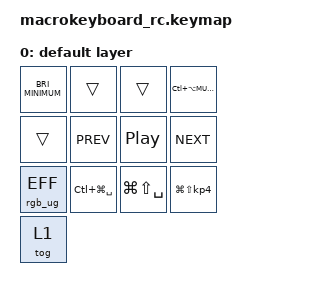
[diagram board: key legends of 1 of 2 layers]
/*
 * Copyright (c) 2021 The ZMK Contributors
 *
 * SPDX-License-Identifier: MIT
 */

#include <behaviors.dtsi>
#include <dt-bindings/zmk/bt.h>
#include <dt-bindings/zmk/keys.h>
#include <dt-bindings/zmk/rgb.h>

#define TIMEOUT 300

&encoder_1 {
    status = "okay";
};

&encoder_2 {
    status = "okay";
};

/ {
    combos {
        compatible = "zmk,combos";

        combo_btclr {
            timeout-ms = <TIMEOUT>;
            key-positions = <1 0>;
            bindings = <&bt BT_CLR>;
        };

        combo_reset {
            timeout-ms = <TIMEOUT>;
            key-positions = <3 2>;
            bindings = <&sys_reset>;
        };

        combo_bootloader {
            timeout-ms = <TIMEOUT>;
            key-positions = <0 3>;
            bindings = <&bootloader>;
        };

        sleep {
            bindings = <&kp LG(LA(K_EJECT))>;
            key-positions = <1 2>;
        };
    };

    behaviors {
        /* DEPRECATED: `inc_dec_cp` will be removed in the future */
    };

    sensors {
        compatible = "zmk,keymap-sensors";
        sensors = <&encoder_1 &encoder_2>;
    };

    keymap0: keymap {
        compatible = "zmk,keymap";

        default_layer {
            label = "default layer";
            bindings = <
&kp C_BRIGHTNESS_MINIMUM  &trans             &trans             &kp LC(LA(C_MUTE))
&trans                    &kp C_PREV         &kp C_PLAY_PAUSE   &kp C_NEXT
&rgb_ug RGB_EFF           &kp LC(LG(SPACE))  &kp LG(LS(SPACE))  &kp LG(LS(KP_N4))
&tog 1
            >;

            sensor-bindings =
                <&inc_dec_kp C_BRIGHTNESS_INC C_BRIGHTNESS_DEC>,
                <&inc_dec_kp C_VOL_UP C_VOL_DN>;
        };

        fn_layer {
            label = "fn layer";
            bindings = <
&kp HOME  &trans  &trans  &kp LG(N0)
&trans    &trans  &trans  &trans
&trans    &trans  &trans  &trans
            >;

            sensor-bindings =
                <&inc_dec_kp PG_UP PG_DN>,
                <&inc_dec_kp LG(PLUS) LG(MINUS)>;
        };
    };
};
